VERSION ""

NS_ :

BS_:

BU_: XXX

BO_ 928 EPB_STATUS: 8 XXX

BO_ 1104 SEATBELT_STATUS: 8 XXX

BO_ 1056 WINDOWS_TURNLED_STATUS: 8 XXX

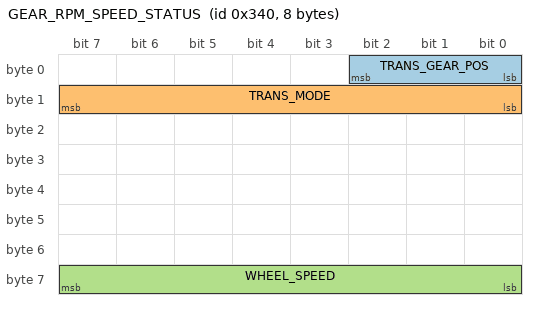
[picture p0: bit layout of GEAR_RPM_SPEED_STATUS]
BO_ 832 GEAR_RPM_SPEED_STATUS: 8 XXX
 SG_ TRANS_GEAR_POS : 0|3@1+ (1,0) [0|1] "" XXX
 SG_ TRANS_MODE : 8|8@1+ (1,0) [0|0] "" XXX
 SG_ WHEEL_SPEED : 63|8@0+ (1,0) [0|255] "KM" XXX

BO_ 821 THROTTLE_STATUS: 8 XXX

BO_ 922 STEERING_ANGLE_STATUS: 8 XXX

CM_ SG_ 832 TRANS_MODE "AT - 85 / MT - 8D";
